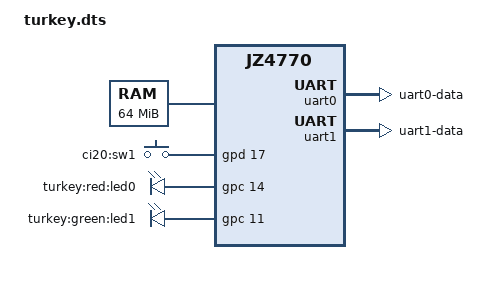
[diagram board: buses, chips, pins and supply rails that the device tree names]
// SPDX-License-Identifier: GPL-2.0
/dts-v1/;

#include "jz4770.dtsi"
#include <dt-bindings/clock/ingenic,tcu.h>
#include <dt-bindings/clock/jz4780-cgu.h>
#include <dt-bindings/gpio/gpio.h>
#include <dt-bindings/input/input.h>
#include <dt-bindings/interrupt-controller/irq.h>
#include <dt-bindings/regulator/active-semi,8865-regulator.h>

/ {
	compatible = "img,ci20", "ingenic,jz4770";

	aliases {
		serial0 = &uart0;
		serial1 = &uart1;
		// serial3 = &uart3;
		// serial4 = &uart4;
	};

	chosen {
		stdout-path = &uart1;
	};

	memory {
		device_type = "memory";
		reg = <0x0 0x2700000
		       0x2700000 0x1900000>;
	};

	gpio-keys {
		compatible = "gpio-keys";

		sw1 {
			label = "ci20:sw1";
			linux,code = <KEY_F13>;
			gpios = <&gpd 17 GPIO_ACTIVE_HIGH>;
			wakeup-source;
		};
	};

	leds {
		compatible = "gpio-leds";

		led0 {
			label = "turkey:red:led0";
			gpios = <&gpc 14 GPIO_ACTIVE_HIGH>;
			linux,default-trigger = "none";
		};

		led1 {
			label = "turkey:green:led1";
			gpios = <&gpc 11 GPIO_ACTIVE_HIGH>;
			linux,default-trigger = "nand-disk";
		};
	};

	// connector {
	// 	compatible = "gpio-usb-b-connector", "usb-b-connector";
	// 	label = "mini-USB";
	// 	type = "mini";

	// 	/*
	// 		* USB OTG is not yet working reliably, the ID detection
	// 		* mechanism tends to fry easily for unknown reasons.
	// 		* Until this is fixed, disable OTG by not providing the
	// 		* ID GPIO to the driver.
	// 		*/
	// 	//id-gpios = <&gpf 18 GPIO_ACTIVE_LOW>;

	// 	vbus-gpios = <&gpb 5 GPIO_ACTIVE_HIGH>;
	// 	vbus-supply = <&otg_vbus>;

	// 	pinctrl-names = "default";
	// 	pinctrl-0 = <&pins_otg>;

	// 	port {
	// 		usb_ep: endpoint {
	// 			remote-endpoint = <&usb_otg_ep>;
	// 		};
	// 	};
	// };
};

&ext {
	clock-frequency = <24000000>;
};

&cgu {
	/*
	 * Use the 32.768 kHz oscillator as the parent of the RTC for a higher
	 * precision.
	 */
	assigned-clocks = <&cgu JZ4780_CLK_OTGPHY>, <&cgu JZ4780_CLK_RTC>;
	assigned-clock-parents = <0>, <&cgu JZ4780_CLK_RTCLK>;
	assigned-clock-rates = <48000000>;
};

&tcu {
	/*
	 * 750 kHz for the system timers and clocksource,
	 * use channel #0 and #1 for the per cpu system timers,
	 * and use channel #2 for the clocksource.
	 *
	 * 3000 kHz for the OST timer to provide a higher
	 * precision clocksource.
	 */
	assigned-clocks = <&tcu TCU_CLK_TIMER0>, <&tcu TCU_CLK_TIMER1>,
					  <&tcu TCU_CLK_TIMER2>, <&tcu TCU_CLK_OST>;
	assigned-clock-rates = <750000>, <750000>, <750000>, <3000000>;
};

// &mmc0 {
// 	status = "okay";

// 	bus-width = <4>;
// 	max-frequency = <50000000>;

// 	pinctrl-names = "default";
// 	pinctrl-0 = <&pins_mmc0>;

// 	cd-gpios = <&gpf 20 GPIO_ACTIVE_LOW>;
// };

// &mmc1 {
// 	status = "okay";

// 	bus-width = <4>;
// 	max-frequency = <50000000>;
// 	non-removable;

// 	pinctrl-names = "default";
// 	pinctrl-0 = <&pins_mmc1>;

// };

&uart0 {
	status = "okay";

	pinctrl-names = "default";
	pinctrl-0 = <&pins_uart0>;
};

&uart1 {
	status = "okay";

	pinctrl-names = "default";
	pinctrl-0 = <&pins_uart1>;
};

// &usb_otg {
// 	port {
// 		usb_otg_ep: endpoint {
// 			remote-endpoint = <&usb_ep>;
// 		};
// 	};
// };

&pinctrl {
	pins_uart0: uart0 {
		function = "uart0";
		groups = "uart0-data";
		bias-disable;
	};

	pins_uart1: uart1 {
		function = "uart1";
		groups = "uart1-data";
		bias-disable;
	};

	pins_otg: otg {
		otg-vbus-pin {
			function = "otg";
			groups = "otg-vbus";
		};

		vbus-pin {
			pins = "PB27";
			bias-disable;
		};
	};
};
